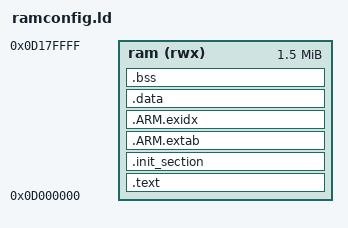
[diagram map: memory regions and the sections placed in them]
/****************************************************************************
 * boards/arm/cxd56xx/spresense/scripts/ramconfig.ld
 *
 *   Copyright 2018 Sony Semiconductor Solutions Corporation
 *
 *   Copyright (C) 2014 Gregory Nutt. All rights reserved.
 *   Author: Gregory Nutt <gnutt@nuttx.org>
 *
 * Redistribution and use in source and binary forms, with or without
 * modification, are permitted provided that the following conditions
 * are met:
 *
 * 1. Redistributions of source code must retain the above copyright
 *    notice, this list of conditions and the following disclaimer.
 * 2. Redistributions in binary form must reproduce the above copyright
 *    notice, this list of conditions and the following disclaimer in
 *    the documentation and/or other materials provided with the
 *    distribution.
 * 3. Neither the name NuttX nor the names of its contributors may be
 *    used to endorse or promote products derived from this software
 *    without specific prior written permission.
 *
 * THIS SOFTWARE IS PROVIDED BY THE COPYRIGHT HOLDERS AND CONTRIBUTORS
 * "AS IS" AND ANY EXPRESS OR IMPLIED WARRANTIES, INCLUDING, BUT NOT
 * LIMITED TO, THE IMPLIED WARRANTIES OF MERCHANTABILITY AND FITNESS
 * FOR A PARTICULAR PURPOSE ARE DISCLAIMED. IN NO EVENT SHALL THE
 * COPYRIGHT OWNER OR CONTRIBUTORS BE LIABLE FOR ANY DIRECT, INDIRECT,
 * INCIDENTAL, SPECIAL, EXEMPLARY, OR CONSEQUENTIAL DAMAGES (INCLUDING,
 * BUT NOT LIMITED TO, PROCUREMENT OF SUBSTITUTE GOODS OR SERVICES; LOSS
 * OF USE, DATA, OR PROFITS; OR BUSINESS INTERRUPTION) HOWEVER CAUSED
 * AND ON ANY THEORY OF LIABILITY, WHETHER IN CONTRACT, STRICT
 * LIABILITY, OR TORT (INCLUDING NEGLIGENCE OR OTHERWISE) ARISING IN
 * ANY WAY OUT OF THE USE OF THIS SOFTWARE, EVEN IF ADVISED OF THE
 * POSSIBILITY OF SUCH DAMAGE.
 *
 ****************************************************************************/

MEMORY
{
    ram (rwx)  : ORIGIN = 0x0d000000, LENGTH = 1536K
}

OUTPUT_ARCH(arm)
ENTRY(__start)         /* Treat __start as the anchor for dead code stripping */
EXTERN(_vectors)       /* Force the vectors to be included in the output */
EXTERN(__stack)        /* Force the __stack to be included in the output */
SECTIONS
{
    .text : {
        _stext = ABSOLUTE(.);
        *(.vectors)
        *(.text .text.*)
        *(.fixup)
        *(.gnu.warning)
        *(.rodata .rodata.*)
        *(.gnu.linkonce.t.*)
        *(.glue_7)
        *(.glue_7t)
        *(.got)
        *(.gcc_except_table)
        *(.gnu.linkonce.r.*)
        _image_modlist_base = .;
        KEEP(*(.modulelist))
        _image_modlist_limit = .;
        _etext = ABSOLUTE(.);
    } > ram

    .init_section : {
        _sinit = ABSOLUTE(.);
        KEEP(*(.init_array .init_array.*))
        _einit = ABSOLUTE(.);
    } > ram

    .ARM.extab : {
        *(.ARM.extab*)
    } > ram

    __exidx_start = ABSOLUTE(.);
    .ARM.exidx : {
        *(.ARM.exidx*)
    } > ram
    __exidx_end = ABSOLUTE(.);

    _eronly = ABSOLUTE(.);

    .data : {
        _sdata = ABSOLUTE(.);
        *(.data .data.*)
        *(.gnu.linkonce.d.*)
        CONSTRUCTORS
        . = ALIGN(4);
        _edata = ABSOLUTE(.);
    } > ram

    .bss : {            /* BSS              */
        _sbss = ABSOLUTE(.);
        *(.bss .bss.*)
        *(.gnu.linkonce.b.*)
        *(COMMON)
        . = ALIGN(4);
        _ebss = ABSOLUTE(.);
    } > ram

    /* __stack symbol is referred from mkspk tool
     * and means the end address of heap region */
    PROVIDE(__stack = ORIGIN(ram) + LENGTH(ram));
    __stack -= DEFINED(__reserved_ramsize) ? __reserved_ramsize : 0;

    ASSERT(_ebss < __stack, "Error: Out of memory")

    /* Stabs debugging sections.    */
    .stab 0 : { *(.stab) }
    .stabstr 0 : { *(.stabstr) }
    .stab.excl 0 : { *(.stab.excl) }
    .stab.exclstr 0 : { *(.stab.exclstr) }
    .stab.index 0 : { *(.stab.index) }
    .stab.indexstr 0 : { *(.stab.indexstr) }
    .comment 0 : { *(.comment) }
    .debug_abbrev 0 : { *(.debug_abbrev) }
    .debug_info 0 : { *(.debug_info) }
    .debug_line 0 : { *(.debug_line) }
    .debug_pubnames 0 : { *(.debug_pubnames) }
    .debug_aranges 0 : { *(.debug_aranges) }
}
